AUTOSAR XML (schema 4-0-3)
package /ComponentTypes
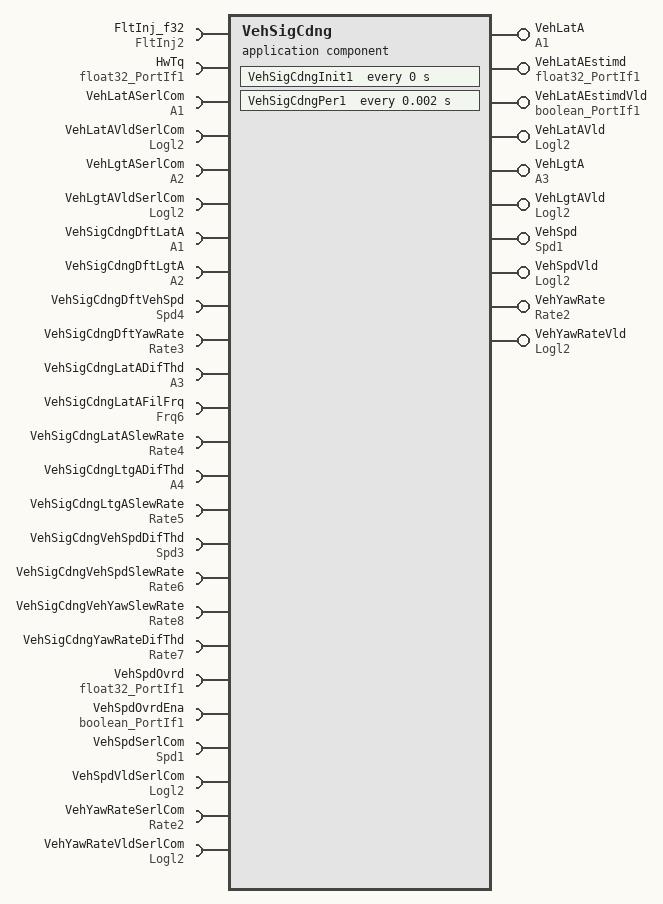
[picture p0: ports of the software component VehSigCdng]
  application sw component type VehSigCdng
    10 x provide port:
      VehLatA: nonqueued-sender-com-spec{data-element=Val, init-value=0}, provided-interface=A1
      VehLatAEstimd: nonqueued-sender-com-spec{data-element=Val, init-value=0}, provided-interface=float32_PortIf1
      VehLatAEstimdVld: nonqueued-sender-com-spec{data-element=Logl, init-value=0}, provided-interface=boolean_PortIf1
      VehLatAVld: nonqueued-sender-com-spec{data-element=Logl, init-value=0}, provided-interface=Logl2
      VehLgtA: nonqueued-sender-com-spec{data-element=Val, init-value=0}, provided-interface=A3
      VehLgtAVld: nonqueued-sender-com-spec{data-element=Logl, init-value=0}, provided-interface=Logl2
      VehSpd: nonqueued-sender-com-spec{data-element=Val, init-value=0}, provided-interface=Spd1
      VehSpdVld: nonqueued-sender-com-spec{data-element=Logl, init-value=0}, provided-interface=Logl2
      VehYawRate: nonqueued-sender-com-spec{data-element=Val, init-value=0}, provided-interface=Rate2
      VehYawRateVld: nonqueued-sender-com-spec{data-element=Logl, init-value=0}, provided-interface=Logl2
    25 x require port:
      FltInj_f32: required-interface=FltInj2
      HwTq: nonqueued-receiver-com-spec{data-element=Val, filter=data-filter-type=ALWAYS, init-value=0}, required-interface=float32_PortIf1
      VehLatASerlCom: nonqueued-receiver-com-spec{data-element=Val, filter=data-filter-type=ALWAYS, init-value=0}, required-interface=A1
      VehLatAVldSerlCom: nonqueued-receiver-com-spec{data-element=Logl, filter=data-filter-type=ALWAYS, init-value=0}, required-interface=Logl2
      VehLgtASerlCom: nonqueued-receiver-com-spec{data-element=Val, filter=data-filter-type=ALWAYS, init-value=0}, required-interface=A2
      VehLgtAVldSerlCom: nonqueued-receiver-com-spec{data-element=Logl, filter=data-filter-type=ALWAYS, init-value=0}, required-interface=Logl2
      VehSigCdngDftLatA: parameter-require-com-spec{init-value=0, parameter=Val}, required-interface=A1
      VehSigCdngDftLgtA: parameter-require-com-spec{init-value=0, parameter=Val}, required-interface=A2
      VehSigCdngDftVehSpd: parameter-require-com-spec{init-value=100, parameter=Val}, required-interface=Spd4
      VehSigCdngDftYawRate: parameter-require-com-spec{init-value=0, parameter=Val}, required-interface=Rate3
      VehSigCdngLatADifThd: parameter-require-com-spec{init-value=0.2, parameter=Val}, required-interface=A3
      VehSigCdngLatAFilFrq: parameter-require-com-spec{init-value=100, parameter=Val}, required-interface=Frq6
      VehSigCdngLatASlewRate: parameter-require-com-spec{init-value=10, parameter=Val}, required-interface=Rate4
      VehSigCdngLtgADifThd: parameter-require-com-spec{init-value=1, parameter=Val}, required-interface=A4
      VehSigCdngLtgASlewRate: parameter-require-com-spec{init-value=50, parameter=Val}, required-interface=Rate5
      VehSigCdngVehSpdDifThd: parameter-require-com-spec{init-value=5, parameter=Val}, required-interface=Spd3
      VehSigCdngVehSpdSlewRate: parameter-require-com-spec{init-value=50, parameter=Val}, required-interface=Rate6
      VehSigCdngVehYawSlewRate: parameter-require-com-spec{init-value=120, parameter=Val}, required-interface=Rate8
      VehSigCdngYawRateDifThd: parameter-require-com-spec{init-value=20, parameter=Val}, required-interface=Rate7
      VehSpdOvrd: nonqueued-receiver-com-spec{data-element=Val, filter=data-filter-type=ALWAYS, init-value=100}, required-interface=float32_PortIf1
      VehSpdOvrdEna: nonqueued-receiver-com-spec{data-element=Logl, filter=data-filter-type=ALWAYS, init-value=0}, required-interface=boolean_PortIf1
      VehSpdSerlCom: nonqueued-receiver-com-spec{data-element=Val, filter=data-filter-type=ALWAYS, init-value=0}, required-interface=Spd1
      VehSpdVldSerlCom: nonqueued-receiver-com-spec{data-element=Logl, filter=data-filter-type=ALWAYS, init-value=0}, required-interface=Logl2
      VehYawRateSerlCom: nonqueued-receiver-com-spec{data-element=Val, filter=data-filter-type=ALWAYS, init-value=0}, required-interface=Rate2
      VehYawRateVldSerlCom: nonqueued-receiver-com-spec{data-element=Logl, filter=data-filter-type=ALWAYS, init-value=0}, required-interface=Logl2
    behavior VehSigCdng_InternalBehavior: data-type-mapping=Nexteer
      ar-typed-per-instance-memorys:
        10 x data, all with sw-calibration-access=READ-ONLY:
          HwTqFilRec: type=FilLpRec1
          LatAFilRec: type=FilLpRec1
          PrevLatA: type=A1
          PrevLatAVld: type=Logl1
          PrevLtgA: type=A3
          PrevLtgAVld: type=Logl1
          PrevVehSpd: type=Spd1
          PrevVehSpdVld: type=Logl1
          PrevYawRate: type=Rate5
          PrevYawRateVld: type=Logl1
      timing event VehSigCdng_InitEvent: start-on-event=VehSigCdngInit1, period=0
      timing event TMT_VehSigCdngPer1: start-on-event=VehSigCdngPer1, period=0.002
      runnable VehSigCdngInit1
      runnable VehSigCdngPer1
        data-receive-point-by-arguments:
          11 x access:
            REC_HwTq_Val: accessed-variable=HwTq.Val
            REC_VehLatASerlCom_Val: accessed-variable=VehLatASerlCom.Val
            REC_VehLatAVldSerlCom_Logl: accessed-variable=VehLatAVldSerlCom.Logl
            REC_VehLgtASerlCom_Val: accessed-variable=VehLgtASerlCom.Val
            REC_VehLgtAVldSerlCom_Logl: accessed-variable=VehLgtAVldSerlCom.Logl
            REC_VehSpdOvrd_Val: accessed-variable=VehSpdOvrd.Val
            REC_VehSpdOvrdEna_Logl: accessed-variable=VehSpdOvrdEna.Logl
            REC_VehSpdSerlCom_Val: accessed-variable=VehSpdSerlCom.Val
            REC_VehSpdVldSerlCom_Logl: accessed-variable=VehSpdVldSerlCom.Logl
            REC_VehYawRateSerlCom_Val: accessed-variable=VehYawRateSerlCom.Val
            REC_VehYawRateVldSerlCom_Logl: accessed-variable=VehYawRateVldSerlCom.Logl
        data-send-points:
          10 x access:
            REC_VehLgtAVld_Logl: accessed-variable=VehLgtAVld.Logl
            REC_VehYawRateVld_Logl: accessed-variable=VehYawRateVld.Logl
            SEND_VehLatA_Val: accessed-variable=VehLatA.Val
            SEND_VehLatAEstimd_Val: accessed-variable=VehLatAEstimd.Val
            SEND_VehLatAEstimdVld_Logl: accessed-variable=VehLatAEstimdVld.Logl
            SEND_VehLatAVld_Logl: accessed-variable=VehLatAVld.Logl
            SEND_VehLgtA_Val: accessed-variable=VehLgtA.Val
            SEND_VehSpd_Val: accessed-variable=VehSpd.Val
            SEND_VehSpdVld_Logl: accessed-variable=VehSpdVld.Logl
            SEND_VehYawRate_Val: accessed-variable=VehYawRate.Val
        sync call SC_FltInj_f32_Oper_1: operation=FltInj_f32.Oper, timeout=0
  swc implementation VehSigCdng_Implementation: behavior=VehSigCdng_InternalBehavior
    code-descriptors:
      code Default: artifact-descriptors=autosar-engineering-object={short-label=Default, category=SWSRC}
